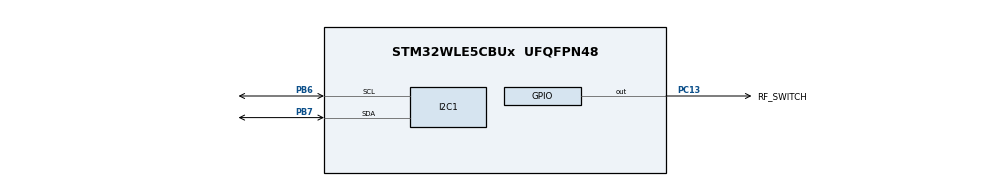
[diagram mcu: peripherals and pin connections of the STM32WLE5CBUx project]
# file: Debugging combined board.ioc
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Mcu.Family=STM32WL
Mcu.Name=STM32WLE5CBUx
Mcu.Package=UFQFPN48
NVIC.PriorityGroup=NVIC_PRIORITYGROUP_4
OSC_IN.Mode=HSE-External-Oscillator
OSC_IN.Signal=RCC_OSC_IN
OSC_OUT.Mode=HSE-External-Oscillator
OSC_OUT.Signal=RCC_OSC_OUT
PA11.Mode=RF-NRESET
PA11.Signal=DEBUG_RF-NRESET
PA12.Mode=RF-BUSY
PA12.Signal=DEBUG_RF-BUSY
PA13.Mode=Serial_Wire
PA13.Signal=DEBUG_JTMS-SWDIO
PA14.Mode=Serial_Wire
PA14.Signal=DEBUG_JTCK-SWCLK
PA4.Mode=SUBGHZSPI-Monitoring
PA4.Signal=DEBUG_SUBGHZSPI-NSSOUT
PA5.Mode=SUBGHZSPI-Monitoring
PA5.Signal=DEBUG_SUBGHZSPI-SCKOUT
PA6.Mode=SUBGHZSPI-Monitoring
PA6.Signal=DEBUG_SUBGHZSPI-MISOOUT
PA7.Mode=SUBGHZSPI-Monitoring
PA7.Signal=DEBUG_SUBGHZSPI-MOSIOUT
PB6.Mode=I2C
PB6.Signal=I2C1_SCL
PB7.Mode=I2C
PB7.Signal=I2C1_SDA
PC13.GPIO_Label=RF_SWITCH
PC13.Signal=GPIO_Output
ProjectManager.HeapSize=0x200
ProjectManager.StackSize=0x400
ProjectManager.TargetToolchain=STM32CubeIDE
RCC.HSE_VALUE=32000000
RCC.HSI_VALUE=16000000
RCC.LSE_VALUE=32768
RCC.VCOOutputFreq_Value=32000000
VP_SUBGHZ_VS_SUBGHZ.Mode=SUBGHZ_Activate
board=custom

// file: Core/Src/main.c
/* USER CODE BEGIN Header */
/**
  ******************************************************************************
  * @file           : main.c
  * @brief          : Main program body
  ******************************************************************************
  * @attention
  *
  * Copyright (c) 2023 STMicroelectronics.
  * All rights reserved.
  *
  * This software is licensed under terms that can be found in the LICENSE file
  * in the root directory of this software component.
  * If no LICENSE file comes with this software, it is provided AS-IS.
  *
  ******************************************************************************
  */
/* USER CODE END Header */
#include "main.h"

/* USER CODE BEGIN Includes */
#include "SX1262.h"
/* USER CODE END Includes */

I2C_HandleTypeDef hi2c1;

SUBGHZ_HandleTypeDef hsubghz;

void SystemClock_Config(void);
static void MX_GPIO_Init(void);
static void MX_I2C1_Init(void);
static void MX_SUBGHZ_Init(void);

int main(void)
{

  /* MCU Configuration--------------------------------------------------------*/

  /* Reset of all peripherals, Initializes the Flash interface and the Systick. */
  HAL_Init();

  /* Configure the system clock */
  SystemClock_Config();

  /* Initialize all configured peripherals */
  MX_GPIO_Init();
  MX_I2C1_Init();
  MX_SUBGHZ_Init();
  /* USER CODE BEGIN 2 */
  LoRaGetStatus();

  /* USER CODE END 2 */

  /* Infinite loop */
  while (1)
  {

  }
}

void SystemClock_Config(void)
{
  RCC_OscInitTypeDef RCC_OscInitStruct = {0};
  RCC_ClkInitTypeDef RCC_ClkInitStruct = {0};

  /** Configure the main internal regulator output voltage
  */
  __HAL_PWR_VOLTAGESCALING_CONFIG(PWR_REGULATOR_VOLTAGE_SCALE2);

  /** Initializes the CPU, AHB and APB buses clocks
  */
  RCC_OscInitStruct.OscillatorType = RCC_OSCILLATORTYPE_MSI;
  RCC_OscInitStruct.MSIState = RCC_MSI_ON;
  RCC_OscInitStruct.MSICalibrationValue = RCC_MSICALIBRATION_DEFAULT;
  RCC_OscInitStruct.MSIClockRange = RCC_MSIRANGE_6;
  RCC_OscInitStruct.PLL.PLLState = RCC_PLL_NONE;
  if (HAL_RCC_OscConfig(&RCC_OscInitStruct) != HAL_OK)
  {
    Error_Handler();
  }

  /** Configure the SYSCLKSource, HCLK, PCLK1 and PCLK2 clocks dividers
  */
  RCC_ClkInitStruct.ClockType = RCC_CLOCKTYPE_HCLK3|RCC_CLOCKTYPE_HCLK
                              |RCC_CLOCKTYPE_SYSCLK|RCC_CLOCKTYPE_PCLK1
                              |RCC_CLOCKTYPE_PCLK2;
  RCC_ClkInitStruct.SYSCLKSource = RCC_SYSCLKSOURCE_MSI;
  RCC_ClkInitStruct.AHBCLKDivider = RCC_SYSCLK_DIV1;
  RCC_ClkInitStruct.APB1CLKDivider = RCC_HCLK_DIV1;
  RCC_ClkInitStruct.APB2CLKDivider = RCC_HCLK_DIV1;
  RCC_ClkInitStruct.AHBCLK3Divider = RCC_SYSCLK_DIV1;

  if (HAL_RCC_ClockConfig(&RCC_ClkInitStruct, FLASH_LATENCY_0) != HAL_OK)
  {
    Error_Handler();
  }
}

static void MX_I2C1_Init(void)
{

  hi2c1.Instance = I2C1;
  hi2c1.Init.Timing = 0x00000E14;
  hi2c1.Init.OwnAddress1 = 0;
  hi2c1.Init.AddressingMode = I2C_ADDRESSINGMODE_7BIT;
  hi2c1.Init.DualAddressMode = I2C_DUALADDRESS_DISABLE;
  hi2c1.Init.OwnAddress2 = 0;
  hi2c1.Init.OwnAddress2Masks = I2C_OA2_NOMASK;
  hi2c1.Init.GeneralCallMode = I2C_GENERALCALL_DISABLE;
  hi2c1.Init.NoStretchMode = I2C_NOSTRETCH_DISABLE;
  if (HAL_I2C_Init(&hi2c1) != HAL_OK)
  {
    Error_Handler();
  }

  /** Configure Analogue filter
  */
  if (HAL_I2CEx_ConfigAnalogFilter(&hi2c1, I2C_ANALOGFILTER_ENABLE) != HAL_OK)
  {
    Error_Handler();
  }

  /** Configure Digital filter
  */
  if (HAL_I2CEx_ConfigDigitalFilter(&hi2c1, 0) != HAL_OK)
  {
    Error_Handler();
  }

}

static void MX_SUBGHZ_Init(void)
{

  hsubghz.Init.BaudratePrescaler = SUBGHZSPI_BAUDRATEPRESCALER_8;
  if (HAL_SUBGHZ_Init(&hsubghz) != HAL_OK)
  {
    Error_Handler();
  }

}

static void MX_GPIO_Init(void)
{
  GPIO_InitTypeDef GPIO_InitStruct = {0};

  /* GPIO Ports Clock Enable */
  __HAL_RCC_GPIOB_CLK_ENABLE();
  __HAL_RCC_GPIOA_CLK_ENABLE();
  __HAL_RCC_GPIOC_CLK_ENABLE();

  /*Configure GPIO pin Output Level */
  HAL_GPIO_WritePin(RF_SWITCH_GPIO_Port, RF_SWITCH_Pin, GPIO_PIN_RESET);

  /*Configure GPIO pins : PA4 PA5 PA6 PA7 */
  GPIO_InitStruct.Pin = GPIO_PIN_4|GPIO_PIN_5|GPIO_PIN_6|GPIO_PIN_7;
  GPIO_InitStruct.Mode = GPIO_MODE_AF_PP;
  GPIO_InitStruct.Pull = GPIO_NOPULL;
  GPIO_InitStruct.Speed = GPIO_SPEED_FREQ_LOW;
  GPIO_InitStruct.Alternate = GPIO_AF13_DEBUG_SUBGHZSPI;
  HAL_GPIO_Init(GPIOA, &GPIO_InitStruct);

  /*Configure GPIO pin : PA11 */
  GPIO_InitStruct.Pin = GPIO_PIN_11;
  GPIO_InitStruct.Mode = GPIO_MODE_AF_PP;
  GPIO_InitStruct.Pull = GPIO_NOPULL;
  GPIO_InitStruct.Speed = GPIO_SPEED_FREQ_LOW;
  GPIO_InitStruct.Alternate = GPIO_AF13_DEBUG_RF;
  HAL_GPIO_Init(GPIOA, &GPIO_InitStruct);

  /*Configure GPIO pin : PA12 */
  GPIO_InitStruct.Pin = GPIO_PIN_12;
  GPIO_InitStruct.Mode = GPIO_MODE_AF_PP;
  GPIO_InitStruct.Pull = GPIO_NOPULL;
  GPIO_InitStruct.Speed = GPIO_SPEED_FREQ_LOW;
  GPIO_InitStruct.Alternate = GPIO_AF6_RF_BUSY;
  HAL_GPIO_Init(GPIOA, &GPIO_InitStruct);

  /*Configure GPIO pin : RF_SWITCH_Pin */
  GPIO_InitStruct.Pin = RF_SWITCH_Pin;
  GPIO_InitStruct.Mode = GPIO_MODE_OUTPUT_PP;
  GPIO_InitStruct.Pull = GPIO_NOPULL;
  GPIO_InitStruct.Speed = GPIO_SPEED_FREQ_LOW;
  HAL_GPIO_Init(RF_SWITCH_GPIO_Port, &GPIO_InitStruct);

}

void Error_Handler(void)
{
  __disable_irq();
  while (1)
  {
  }
}
